# netx90_app register map
File version: 1.0
CPU: CM4 r0p1, little endian, MPU, FPU, 4 interrupt priority bits, 78 interrupts
Registers are 32-bit, read-write, reset 0x0 unless marked. A register's access mark holds for its fields unless they carry their own. Offsets are from the block's base; [hi:lo] are bit positions.

## hif_asyncmem_ctrl
Base 0xFF401500
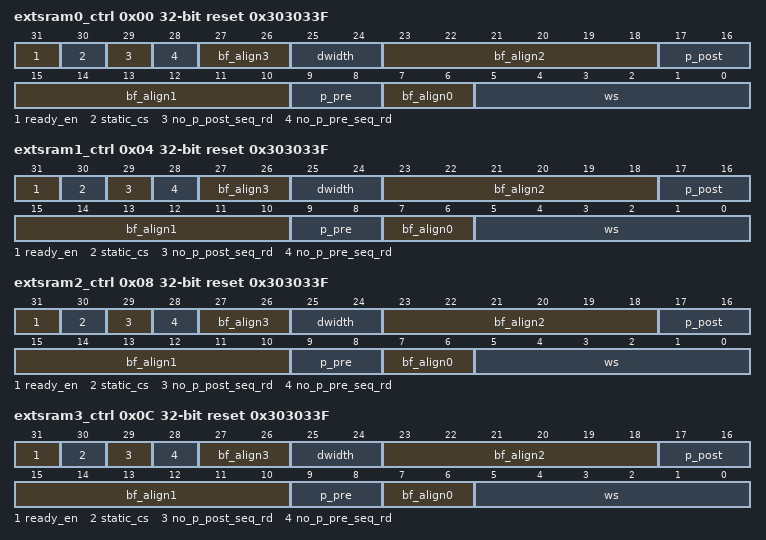
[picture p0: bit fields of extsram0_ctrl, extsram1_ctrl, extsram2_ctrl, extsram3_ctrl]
0x00 extsram0_ctrl reset 0x303033F (reset mask 0xF303033F) — Control Register for external bus interface and wait-states for chip-select 0 area. External addresses always be byte addresses. For additional byte-enables/DQM signals view netX pinout documentation. For all wait state configuration 1 cycle is 1 netx system clock cycle, i.e. 10ns for netX running on 100MHz at normal operation. Note: Pause and data width configuration is compatible to netx500/100 and netx50. Note: This register can be protected by the register MODULE_FIREWALL_CTRL.firewall_cfg_hifmemctrl.
  [31] ready_en — Ready Signal Enable. 0: Access timing is only controlled by Wait-State and Pre/Post-Pause configuration above. 1: Use external ready input to stretch Wait-State phase. Wait-States and Pre/Post-Pauses will be done according to configuration above. However Wait-State phase can be extended by an external device by holding netX ready input inactive. Data access cycle is done after external device sets netX ready input to active state. Note: An external device must assert ready to inactive state while Wait-States phase is running (defined by ws in this register). Ready input sampling and latency takes 20ns. Hence ws must be set to a value greater than 2 for proper functionality using ready. The value must be increased if there is a ready setup time of the ready generating external device. Note: For detailed ready input configuration and handling view ext_rdy_cfg register description.
  [30] static_cs — Static chip-select signal generation. 0: No static chip-select signal generation 1: Static chip-select signal generation enabled (e.g. for i80 displays). All chip-select signals will return to inactive (high) level when no access is performed by default (when this bit is not set). However some devices (e.g. some i80 displays) require subsequent access without chip-select becoming inactive in between. For that purpose 'static_cs' bit can be set. Chip-select will remain active once an access was performed to this chip-select address-area until an access targets another chip-select address-area. Hence, for proper i80 sequence, software must avoid that the current access sequence is interrupted by an access to another chip-select area (including SDRAM access of this memory interface), e.g. cause by interrupt execution, other masters or SDRAM refresh generation. To release chip-select to idle state, - access another chip-select area of this memory interface or - clear the 'static_cs' bit of this chip-select area or - disable this chip-select area (set 'dwidth' to '11'). Note: Clearing the 'static_cs'-bit while an access is running to this chip-select area will have no impact on the current access. However disabling the whole chip-select area while an access is running could lead to an invalid access. Note: This is a new feature since netx51/52.
  [29] no_p_post_seq_rd — No Post-Pause insertion between sequential reads. 0: Post-Pause will be inserted after each read access. 1: Disable Post-Pause between sequential reads. Note: Default setting '0' is for netx100/50 compatibility only. Typically there is no need of Post-Pause insertion between sequential reads. A Post-Pause will always be inserted if the next access addresses another chip-select area, is a write access or is not predictable by the memory controller.
  [28] no_p_pre_seq_rd — No Pre-Pause insertion between sequential reads. 0: Pre-Pause will be inserted after each read access. 1: Disable Pre-Pause between sequential reads. Note: default setting '0' is for netx100/50 compatibility only. Typically there is no need of Pre-Pause insertion between sequential reads.
  [27:26] bf_align3 — bitField alignment value for aeabi compatibility
  [25:24] dwidth — Data bus width of ExtMem0 area. 00 : 8bit memory device connected to this chip-select address area. 01 : 16bit memory device connected to this chip-select address area. 10 : reserved. 11 : memory is disabled, related chip-select signal can be used for other purpose (e.g. as PIO). Note: Chip-selects are disabled by default. However it could be possible that they are enabled during netX boot phase to search for boot device. View bootloader information for this. Note: When chip-select is disabled related netX IO can be used for other functions. View memory interface multiplex options or netX pinning for more information. Note: All access to disabled chip-select area will be ignored. No wait will be generated to requesting master. Read data will be unvalid. External MI signal states will not change.
  [23:18] bf_align2 — bitField alignment value for aeabi compatibility
  [17:16] p_post — Post-Pause (0 - 3 cycles) of ExtMem0 area. Additional wait-states to match memory device Output-Disable or Address-Hold times. If programmed value is not 0, this Post-Pause will be inserted at external access end after Wait-State phase and data access cycle. Address, chip-select and byte-enable signals will remain stable in this phase. but nRD-signal and nWR-signal will become inactive high. After write access netX memory controller will always insert at least 1 Post-Pause cycle to generate positive edge on nWR-signal.
  [15:10] bf_align1 — bitField alignment value for aeabi compatibility
  [9:8] p_pre — Pre-Pause (0 - 3 cycles) of ExtMem0 area. Additional wait-states to match memory device setup times. If programmed value is not 0, this Pre-Pause will be inserted at external access start before Wait-State phase is started. Address, chip-select and byte-enable signals will be stable in this phase. but nRD-signal and nWR-signal remains inactive high. Note: The Pre-Pause could be extended by 1 cycle under certain conditions by netX memory controller. E.g. this becomes necessary for some access sequences (e.g. write-after-read or chip-select area change) to avoid collisions on external data bus.
  [7:6] bf_align0 — bitField alignment value for aeabi compatibility
  [5:0] ws — Wait-States (0 - 63 cycles) of ExtMem0 area. During read access nRD-signal active low phase is ws+1. During write access nWR-signal active low phase is ws+1.. Address, chip-select and byte-enable signals remain stable in this phase. After ws wait-cycles have passed signals remain stable and final data-access cycle is done. To match memory device data access time tACC: program WS=ceil(tACC/10ns)-1.
0x04 extsram1_ctrl reset 0x303033F (reset mask 0xF303033F) — Control Register for external bus interface and wait-states for chip-select 1 area. For detailed register description view extsram0_ctrl register. Note: This register can be protected by the register MODULE_FIREWALL_CTRL.firewall_cfg_hifmemctrl.
  [31] ready_en — Ready Signal Enable.
  [30] static_cs — Static chip-select signal generation.
  [29] no_p_post_seq_rd — No Post-Pause insertion between sequential reads.
  [28] no_p_pre_seq_rd — No Pre-Pause insertion between sequential reads.
  [27:26] bf_align3 — bitField alignment value for aeabi compatibility
  [25:24] dwidth — Data bus width of ExtMem1 area. Note: This chip-select is disabled by default and may be shared with other functions. View memory interface multiplex options for more information.
  [23:18] bf_align2 — bitField alignment value for aeabi compatibility
  [17:16] p_post — Post-Pause (0 - 3 cycles) of ExtMem1 area.
  [15:10] bf_align1 — bitField alignment value for aeabi compatibility
  [9:8] p_pre — Pre-Pause (0 - 3 cycles) of ExtMem1 area.
  [7:6] bf_align0 — bitField alignment value for aeabi compatibility
  [5:0] ws — Wait-States (0 - 63 cycles) of ExtMem1 area.
0x08 extsram2_ctrl reset 0x303033F (reset mask 0xF303033F) — Control Register for external bus interface and wait-states for chip-select 2 area. For detailed register description view extsram0_ctrl register. Note: This register can be protected by the register MODULE_FIREWALL_CTRL.firewall_cfg_hifmemctrl.
  [31] ready_en — Ready Signal Enable.
  [30] static_cs — Static chip-select signal generation.
  [29] no_p_post_seq_rd — No Post-Pause insertion between sequential reads.
  [28] no_p_pre_seq_rd — No Pre-Pause insertion between sequential reads.
  [27:26] bf_align3 — bitField alignment value for aeabi compatibility
  [25:24] dwidth — Data bus width of ExtMem2 area. Note: This chip-select is disabled by default and may be shared with other functions. View memory interface multiplex options for more information.
  [23:18] bf_align2 — bitField alignment value for aeabi compatibility
  [17:16] p_post — Post-Pause (0 - 3 cycles) of ExtMem2 area.
  [15:10] bf_align1 — bitField alignment value for aeabi compatibility
  [9:8] p_pre — Pre-Pause (0 - 3 cycles) of ExtMem2 area.
  [7:6] bf_align0 — bitField alignment value for aeabi compatibility
  [5:0] ws — Wait-States (0 - 63 cycles) of ExtMem2 area.
0x0C extsram3_ctrl reset 0x303033F (reset mask 0xF303033F) — Control Register for external bus interface and wait-states for ExtMem1 chip-select 3 area. For detailed register description view extsram0_ctrl register. Note: This register can be protected by the register MODULE_FIREWALL_CTRL.firewall_cfg_hifmemctrl.
  [31] ready_en — Ready Signal Enable.
  [30] static_cs — Static chip-select signal generation.
  [29] no_p_post_seq_rd — No Post-Pause insertion between sequential reads.
  [28] no_p_pre_seq_rd — No Pre-Pause insertion between sequential reads.
  [27:26] bf_align3 — bitField alignment value for aeabi compatibility
  [25:24] dwidth — Data bus width of ExtMem3 area. Note: This chip-select is disabled by default and may be shared with other functions. View memory interface multiplex options for more information.
  [23:18] bf_align2 — bitField alignment value for aeabi compatibility
  [17:16] p_post — Post-Pause (0 - 3 cycles) of ExtMem3 area.
  [15:10] bf_align1 — bitField alignment value for aeabi compatibility
  [9:8] p_pre — Pre-Pause (0 - 3 cycles) of ExtMem3 area.
  [7:6] bf_align0 — bitField alignment value for aeabi compatibility
  [5:0] ws — Wait-States (0 - 63 cycles) of ExtMem3 area.
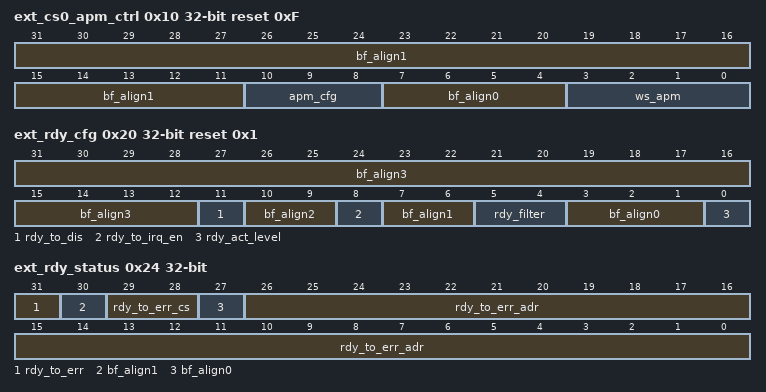
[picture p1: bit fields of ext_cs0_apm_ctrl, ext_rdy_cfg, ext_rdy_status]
0x10 ext_cs0_apm_ctrl reset 0xF (reset mask 0x70F) — Asynchronous Page Mode (APM) Control Register for ExtMem0 chip-select area. Only ExtMem0 chip-select area supports fast Asynchronous-Page-Mode (APM) Access. Note: This register can be protected by the register MODULE_FIREWALL_CTRL.firewall_cfg_hifmemctrl.
  [31:11] bf_align1 — bitField alignment value for aeabi compatibility
  [10:8] apm_cfg — APM configuration. 000 : read bursts are disabled 001 : 1 D-word (4 byte) address boundary for APM 010 : 2 D-word (8 byte) address boundary for APM 011 : 4 D-word (16 byte) address boundary for APM 100 : 8 D-word (32 byte) address boundary for APM 101 : 16 D-word (64 byte) address boundary for APM 110 : 32 D-word (128 byte) address boundary for APM all other settings are reserved. APM burst length programming is related to system address boundaries. For correct programming device data width and page size must be considdered. Examples: 8 bit device providing 4 word page: Page size is 1 D-word. Hence program '000'. 16 bit device providing 8 word page: Page size is 4 D-word. Hence program '011'. 32 bit device providing 32 word page: Page size is 32 D-word. Hence program '110'. Note: When device page size exceeds 32 D-words (128 byte), set 'apm_cfg' bit field to '110'.
  [7:4] bf_align0 — bitField alignment value for aeabi compatibility
  [3:0] ws_apm — APM read burst wait-states (0 - 15 cycles). If APM is enabled by apm_cfg-bits, first read access is done with number of wait-states programmed in extsram0_ctrl register. Following read accesses to ExtMem0 chip-select area are done with wait-states programmed here until APM-accesses are terminated. If netX runs internal read bursts only netX address lines will change. chip-select and nRD signals will remain active low. APM accesses are terminated if chip-select of ExtMem0 address area becomes inactive, if write access is done between read accesses or if read access is leaving APM address boundary. Note: Chip-select remains active low after read even if no further access is currently requested by netX. Chip-select will become inactive, if access to another external chip-select area is requested or if external memory bus is shared with SDRAM and netX SDRAM controller performs access or refresh cycles.
0x20 ext_rdy_cfg reset 0x1 (reset mask 0x931) — External Memory Ready Control Register. Note: Timeout is generated if ready usage is enabled by the extsramX_ctrl registers and is not asserted to active state within 10us. Note: This register can be protected by the register MODULE_FIREWALL_CTRL.firewall_cfg_hifmemctrl.
  [31:12] bf_align3 — bitField alignment value for aeabi compatibility
  [11] rdy_to_dis — Ready Timeout Disable By default ready timeout is enabled. Timeout is generated if ready usage is enabled by the extsramX_ctrl registers and is not asserted to active state within 10us (1024 system clocks). If an external device requires even longer response time, ready timeout can be disabled by setting this bit. However be careful: If ready is not asserted anytime, netX system will stall. Escape from this can only be achieved by Hardware Reset (e.g. by system watchdog timeout). 0: Ready timeout is enabled. 1: Ready timeout is disabled.
  [10:9] bf_align2 — bitField alignment value for aeabi compatibility
  [8] rdy_to_irq_en — Ready Timeout IRQ Enable 0: No IRQ generation in case of ready timeout. 1: generate an IRQ in case of ready timeout. Note: Ready Timeout IRQ is part of netX System Status IRQ (view system_status register in area asic_ctrl and VIC registers)
  [7:6] bf_align1 — bitField alignment value for aeabi compatibility
  [5:4] rdy_filter — Ready Input Filter. Ready input filtering is implemented to avoid false ready active detection especially if ready signal is not always driven and ready active state is realized by pull-up or down resistors. 00: Ready active state is detected after ready signal is sampled once in active state (no filtering). 01: Ready active state is detected after ready signal is consecutively sampled twice in active state. 10: Ready active state is detected after ready signal is consecutively sampled 3 times in active state. 11: Ready active state is detected after ready signal is consecutively sampled 4 times in active state. Note: If ready is sampled in inactive state, active state counting will restart at zero. Note: If ready input filering is enabled, access time will be increased at least by filter time (ready is sampled any 10ns).
  [3:1] bf_align0 — bitField alignment value for aeabi compatibility
  [0] rdy_act_level — Ready Active Level 0: Ready is active low / stall access while ready input is high. 1: Ready is active high / stall access while ready input is low.
0x24 ext_rdy_status (reset mask 0xB7FFFFFF) — External Memory Ready Status Register. Note: Timeout is generated if ready usage is enabled by the extsramX_ctrl registers and is not asserted to active state within 10us. Note: This register can be protected by the register MODULE_FIREWALL_CTRL.firewall_cfg_hifmemctrl.
  [31] rdy_to_err — Ready Timeout Error. This bit is set if a ready timeout error is detected. The external address and chip-select will be logged then in the lower bits of this register. An IRQ/Abort will be generated if enabled by the ext_rdy_cfg register. Writing a '1' here will reset this bit and the IRQ. Note: If multiple timeouts are detected, the first timeout address and chip-select will be logged. Note: Ready Timeout IRQ is part of netX System Status IRQ (view system_status register in area asic_ctrl and VIC registers)
  [30] bf_align1 — bitField alignment value for aeabi compatibility
  [29:28] rdy_to_err_cs — Ready timeout error chip-select logging.
  [27] bf_align0 — bitField alignment value for aeabi compatibility
  [26:0] rdy_to_err_adr — Ready timeout error address logging.
